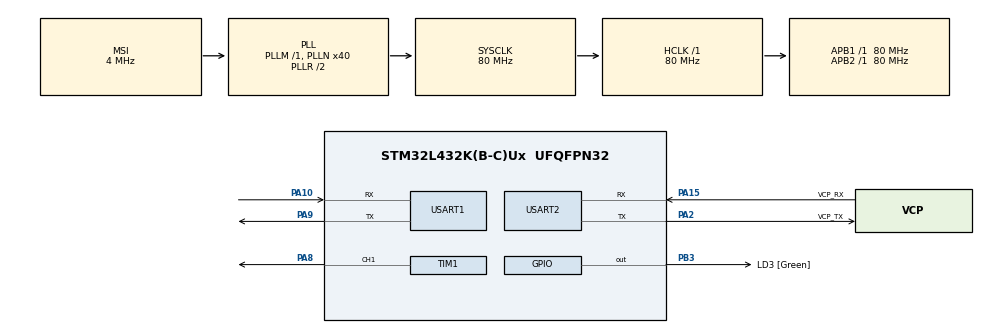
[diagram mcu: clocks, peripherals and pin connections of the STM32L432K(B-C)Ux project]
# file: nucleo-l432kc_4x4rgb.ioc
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Dma.Request0=TIM1_CH1
Dma.Request1=USART1_RX
Dma.TIM1_CH1.0.Direction=DMA_MEMORY_TO_PERIPH
Dma.TIM1_CH1.0.Instance=DMA1_Channel2
Dma.TIM1_CH1.0.MemDataAlignment=DMA_MDATAALIGN_BYTE
Dma.TIM1_CH1.0.MemInc=DMA_MINC_ENABLE
Dma.TIM1_CH1.0.Mode=DMA_NORMAL
Dma.TIM1_CH1.0.PeriphDataAlignment=DMA_PDATAALIGN_HALFWORD
Dma.TIM1_CH1.0.PeriphInc=DMA_PINC_DISABLE
Dma.TIM1_CH1.0.Priority=DMA_PRIORITY_VERY_HIGH
Dma.USART1_RX.1.Direction=DMA_PERIPH_TO_MEMORY
Dma.USART1_RX.1.Instance=DMA1_Channel5
Dma.USART1_RX.1.MemDataAlignment=DMA_MDATAALIGN_BYTE
Dma.USART1_RX.1.MemInc=DMA_MINC_ENABLE
Dma.USART1_RX.1.Mode=DMA_CIRCULAR
Dma.USART1_RX.1.PeriphDataAlignment=DMA_PDATAALIGN_BYTE
Dma.USART1_RX.1.PeriphInc=DMA_PINC_DISABLE
Dma.USART1_RX.1.Priority=DMA_PRIORITY_LOW
FREERTOS.BinarySemaphores01=sem_printPermission,Dynamic,NULL
FREERTOS.Tasks01=receiverTask,40,256,StartReceiverTask,Default,NULL,Dynamic,NULL,NULL;startWifiClickT,8,256,_startWifiClickTask,Default,NULL,Dynamic,NULL,NULL
FREERTOS.Timers01=updateScreenTimer,updateScreenTimerCallback,osTimerPeriodic,Default,NULL,Dynamic,NULL
FREERTOS.configMINIMAL_STACK_SIZE=256
FREERTOS.configTIMER_TASK_PRIORITY=5
FREERTOS.configTOTAL_HEAP_SIZE=10000
FREERTOS.configUSE_NEWLIB_REENTRANT=1
Mcu.Family=STM32L4
Mcu.Name=STM32L432K(B-C)Ux
Mcu.Package=UFQFPN32
NVIC.DMA1_Channel2_IRQn=true\:5\:0\:false\:false\:true\:true\:false\:true\:true
NVIC.DMA1_Channel5_IRQn=true\:5\:0\:false\:false\:true\:true\:false\:true\:true
NVIC.PriorityGroup=NVIC_PRIORITYGROUP_4
NVIC.TIM1_CC_IRQn=true\:5\:0\:false\:false\:true\:true\:true\:true\:true
NVIC.TIM1_UP_TIM16_IRQn=true\:15\:0\:false\:false\:true\:false\:false\:true\:true
NVIC.TimeBase=TIM1_UP_TIM16_IRQn
NVIC.TimeBaseIP=TIM16
NVIC.USART1_IRQn=true\:5\:0\:false\:false\:true\:true\:true\:true\:true
NVIC.USART2_IRQn=true\:5\:0\:false\:false\:true\:true\:true\:true\:true
PA0.GPIO_Label=MCO [High speed clock in]
PA0.Mode=HSE-External-Clock-Source-for-LittleOrca
PA0.Signal=RCC_CK_IN
PA10.Mode=Asynchronous
PA10.Signal=USART1_RX
PA13\ (JTMS-SWDIO).GPIO_Label=SWDIO
PA13\ (JTMS-SWDIO).Mode=Serial_Wire
PA13\ (JTMS-SWDIO).Signal=SYS_JTMS-SWDIO
PA14\ (JTCK-SWCLK).GPIO_Label=SWCLK
PA14\ (JTCK-SWCLK).Mode=Serial_Wire
PA14\ (JTCK-SWCLK).Signal=SYS_JTCK-SWCLK
PA15\ (JTDI).GPIO_Label=VCP_RX
PA15\ (JTDI).Mode=Asynchronous
PA15\ (JTDI).Signal=USART2_RX
PA2.GPIO_Label=VCP_TX
PA2.Mode=Asynchronous
PA2.Signal=USART2_TX
PA8.GPIO_PuPd=GPIO_PULLDOWN
PA8.GPIO_Speed=GPIO_SPEED_FREQ_VERY_HIGH
PA8.Signal=S_TIM1_CH1
PA9.Mode=Asynchronous
PA9.Signal=USART1_TX
PB3\ (JTDO-TRACESWO).GPIO_Label=LD3 [Green]
PB3\ (JTDO-TRACESWO).GPIO_Speed=GPIO_SPEED_FREQ_LOW
PB3\ (JTDO-TRACESWO).PinState=GPIO_PIN_RESET
PB3\ (JTDO-TRACESWO).Signal=GPIO_Output
PC14-OSC32_IN\ (PC14).Mode=LSE-External-Oscillator
PC14-OSC32_IN\ (PC14).Signal=RCC_OSC32_IN
PC15-OSC32_OUT\ (PC15).Mode=LSE-External-Oscillator
PC15-OSC32_OUT\ (PC15).Signal=RCC_OSC32_OUT
ProjectManager.HeapSize=0x200
ProjectManager.StackSize=0x400
ProjectManager.TargetToolchain=STM32CubeIDE
RCC.ADCFreq_Value=16000000
RCC.AHBFreq_Value=80000000
RCC.APB1Freq_Value=80000000
RCC.APB1TimFreq_Value=80000000
RCC.APB2Freq_Value=80000000
RCC.APB2TimFreq_Value=80000000
RCC.CortexFreq_Value=80000000
RCC.HCLKFreq_Value=80000000
RCC.HSE_VALUE=8000000
RCC.HSI16_VALUE=16000000
RCC.HSI48_VALUE=48000000
RCC.HSI_VALUE=16000000
RCC.MSI_VALUE=4000000
RCC.PLLMUL=RCC_PLLMUL_4
RCC.PLLN=40
RCC.SYSCLKFreq_VALUE=80000000
RCC.SYSCLKSource=RCC_SYSCLKSOURCE_PLLCLK
RCC.USBFreq_Value=16000000
RCC.VCOOutputFreq_Value=160000000
SH.S_TIM1_CH1.0=TIM1_CH1,PWM Generation1 CH1
TIM1.AutoReloadPreload=TIM_AUTORELOAD_PRELOAD_ENABLE
TIM1.BreakPolarity=TIM_BREAKPOLARITY_HIGH
TIM1.Channel-PWM\ Generation1\ CH1=TIM_CHANNEL_1
TIM1.OCFastMode_PWM-PWM\ Generation1\ CH1=TIM_OCFAST_ENABLE
TIM1.OCIdleState_1=TIM_OCIDLESTATE_RESET
TIM1.OCPolarity_1=TIM_OCPOLARITY_HIGH
TIM1.Period=100
TIM1.Pulse-PWM\ Generation1\ CH1=100
TIM1.TIM_MasterOutputTrigger=TIM_TRGO_RESET
TIM1.TIM_MasterOutputTrigger2=TIM_TRGO2_RESET
USART1.VirtualMode-Asynchronous=VM_ASYNC
USART2.VirtualMode-Asynchronous=VM_ASYNC
VP_FREERTOS_VS_CMSIS_V2.Mode=CMSIS_V2
VP_SYS_VS_tim16.Mode=TIM16
board=NUCLEO-L432KC

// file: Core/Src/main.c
/* USER CODE BEGIN Header */
/**
  ******************************************************************************
  * @file           : main.c
  * @brief          : Main program body
  ******************************************************************************
  * @attention
  *
  * Copyright (c) 2023 STMicroelectronics.
  * All rights reserved.
  *
  * This software is licensed under terms that can be found in the LICENSE file
  * in the root directory of this software component.
  * If no LICENSE file comes with this software, it is provided AS-IS.
  *
  ******************************************************************************
  */
/* USER CODE END Header */
#include "main.h"
#include "cmsis_os.h"
#include "dma.h"
#include "tim.h"
#include "usart.h"
#include "gpio.h"

void SystemClock_Config(void);
void MX_FREERTOS_Init(void);

int main(void)
{

  /* MCU Configuration--------------------------------------------------------*/

  /* Reset of all peripherals, Initializes the Flash interface and the Systick. */
  HAL_Init();

  /* Configure the system clock */
  SystemClock_Config();

  /* Initialize all configured peripherals */
  MX_GPIO_Init();
  MX_DMA_Init();
  MX_USART2_UART_Init();
  MX_TIM1_Init();
  MX_USART1_UART_Init();

  /* Init scheduler */
  osKernelInitialize();  /* Call init function for freertos objects (in freertos.c) */
  MX_FREERTOS_Init();

  /* Start scheduler */
  osKernelStart();
  /* We should never get here as control is now taken by the scheduler */
  /* Infinite loop */
  while (1)
  {

  }
}

void SystemClock_Config(void)
{
  RCC_OscInitTypeDef RCC_OscInitStruct = {0};
  RCC_ClkInitTypeDef RCC_ClkInitStruct = {0};

  /** Configure the main internal regulator output voltage
  */
  if (HAL_PWREx_ControlVoltageScaling(PWR_REGULATOR_VOLTAGE_SCALE1) != HAL_OK)
  {
    Error_Handler();
  }

  /** Configure LSE Drive Capability
  */
  HAL_PWR_EnableBkUpAccess();
  __HAL_RCC_LSEDRIVE_CONFIG(RCC_LSEDRIVE_LOW);

  /** Initializes the RCC Oscillators according to the specified parameters
  * in the RCC_OscInitTypeDef structure.
  */
  RCC_OscInitStruct.OscillatorType = RCC_OSCILLATORTYPE_LSE|RCC_OSCILLATORTYPE_MSI;
  RCC_OscInitStruct.LSEState = RCC_LSE_ON;
  RCC_OscInitStruct.MSIState = RCC_MSI_ON;
  RCC_OscInitStruct.MSICalibrationValue = 0;
  RCC_OscInitStruct.MSIClockRange = RCC_MSIRANGE_6;
  RCC_OscInitStruct.PLL.PLLState = RCC_PLL_ON;
  RCC_OscInitStruct.PLL.PLLSource = RCC_PLLSOURCE_MSI;
  RCC_OscInitStruct.PLL.PLLM = 1;
  RCC_OscInitStruct.PLL.PLLN = 40;
  RCC_OscInitStruct.PLL.PLLP = RCC_PLLP_DIV7;
  RCC_OscInitStruct.PLL.PLLQ = RCC_PLLQ_DIV2;
  RCC_OscInitStruct.PLL.PLLR = RCC_PLLR_DIV2;
  if (HAL_RCC_OscConfig(&RCC_OscInitStruct) != HAL_OK)
  {
    Error_Handler();
  }

  /** Initializes the CPU, AHB and APB buses clocks
  */
  RCC_ClkInitStruct.ClockType = RCC_CLOCKTYPE_HCLK|RCC_CLOCKTYPE_SYSCLK
                              |RCC_CLOCKTYPE_PCLK1|RCC_CLOCKTYPE_PCLK2;
  RCC_ClkInitStruct.SYSCLKSource = RCC_SYSCLKSOURCE_PLLCLK;
  RCC_ClkInitStruct.AHBCLKDivider = RCC_SYSCLK_DIV1;
  RCC_ClkInitStruct.APB1CLKDivider = RCC_HCLK_DIV1;
  RCC_ClkInitStruct.APB2CLKDivider = RCC_HCLK_DIV1;

  if (HAL_RCC_ClockConfig(&RCC_ClkInitStruct, FLASH_LATENCY_4) != HAL_OK)
  {
    Error_Handler();
  }

  /** Enable MSI Auto calibration
  */
  HAL_RCCEx_EnableMSIPLLMode();
}

void HAL_TIM_PeriodElapsedCallback(TIM_HandleTypeDef *htim)
{
  if (htim->Instance == TIM16) {
    HAL_IncTick();
  }
}

void Error_Handler(void)
{
  __disable_irq();
  while (1)
  {
  }
}

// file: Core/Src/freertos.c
/* USER CODE BEGIN Header */
/**
  ******************************************************************************
  * File Name          : freertos.c
  * Description        : Code for freertos applications
  ******************************************************************************
  * @attention
  *
  * Copyright (c) 2023 STMicroelectronics.
  * All rights reserved.
  *
  * This software is licensed under terms that can be found in the LICENSE file
  * in the root directory of this software component.
  * If no LICENSE file comes with this software, it is provided AS-IS.
  *
  ******************************************************************************
  */
/* USER CODE END Header */

#include "FreeRTOS.h"
#include "task.h"
#include "main.h"
#include "cmsis_os.h"

/* USER CODE BEGIN Includes */
#include "wifiClick.h"

/* USER CODE END Includes */

/* USER CODE BEGIN Variables */

uint8_t updateLedMatrix = 0;

uint8_t newDataAvailable = 0;

uint8_t dataToPrint;

/* USER CODE END Variables */
/* Definitions for receiverTask */
osThreadId_t receiverTaskHandle;
const osThreadAttr_t receiverTask_attributes = {
  .name = "receiverTask",
  .stack_size = 256 * 4,
  .priority = (osPriority_t) osPriorityHigh,
};
/* Definitions for startWifiClickT */
osThreadId_t startWifiClickTHandle;
const osThreadAttr_t startWifiClickT_attributes = {
  .name = "startWifiClickT",
  .stack_size = 256 * 4,
  .priority = (osPriority_t) osPriorityLow,
};
/* Definitions for updateScreenTimer */
osTimerId_t updateScreenTimerHandle;
const osTimerAttr_t updateScreenTimer_attributes = {
  .name = "updateScreenTimer"
};
/* Definitions for sem_printPermission */
osSemaphoreId_t sem_printPermissionHandle;
const osSemaphoreAttr_t sem_printPermission_attributes = {
  .name = "sem_printPermission"
};

void StartReceiverTask(void *argument);
void _startWifiClickTask(void *argument);
void updateScreenTimerCallback(void *argument);

void MX_FREERTOS_Init(void); /* (MISRA C 2004 rule 8.1) */

void MX_FREERTOS_Init(void) {

  /* Create the semaphores(s) */
  /* creation of sem_printPermission */
  sem_printPermissionHandle = osSemaphoreNew(1, 1, &sem_printPermission_attributes);

  /* Create the timer(s) */
  /* creation of updateScreenTimer */
  updateScreenTimerHandle = osTimerNew(updateScreenTimerCallback, osTimerPeriodic, NULL, &updateScreenTimer_attributes);

  /* Create the thread(s) */
  /* creation of receiverTask */
  receiverTaskHandle = osThreadNew(StartReceiverTask, NULL, &receiverTask_attributes);

  /* creation of startWifiClickT */
  startWifiClickTHandle = osThreadNew(_startWifiClickTask, NULL, &startWifiClickT_attributes);

}

/**

    @brief Receiver task.

    This task continuously checks for new data and triggers the printing of the data on the LED matrix
    if both the updateLedMatrix flag and newDataAvailable flag are set. Once the data is printed,
    it clears the updateLedMatrix flag and sets the newDataAvailable flag.

    @param argument Pointer to the argument passed to the function (unused).
    */

void StartReceiverTask(void *argument)
{
  /* USER CODE BEGIN StartReceiverTask */
  for(;;)
  {
	  if(updateLedMatrix && newDataAvailable)
	  {
		  updateLedMatrix = 0;
		  newDataAvailable = 1;

		  printDataOnMatrix(&dataToPrint);
	  }

    osDelay(1);
  }
  /* USER CODE END StartReceiverTask */
}

void _startWifiClickTask(void *argument)
{
  /* USER CODE BEGIN _startWifiClickTask */
	StartWifiClick(&dataToPrint);
	osThreadExit();
  /* USER CODE END _startWifiClickTask */
}

/* updateScreenTimerCallback function */
void updateScreenTimerCallback(void *argument)
{
  /* USER CODE BEGIN updateScreenTimerCallback */
	updateLedMatrix = 1;
  /* USER CODE END updateScreenTimerCallback */
}

/* USER CODE BEGIN Application */

/* TODO: @Thomas diese bei dir dann aufrufen wenn neue Daten kommen */
void NewDataAvailableCallback()
{
	newDataAvailable = 1;
}

/* USER CODE END Application */
